# SDHCI register map
File version: 3
SD host controller, SD Host Controller Specification version 3.00 register set
Registers are read-write, no defined reset value unless marked. A register's access mark holds for its fields unless they carry their own. Offsets are from the block's base; lines under a group give offsets from that group; [hi:lo] are bit positions; {n}, {i} and the like mark numbered series; 'fields as' and 'values as' point back to an identical list; <NAME> marks a mode.

## Memory map
0x00000000 SDHCI size 0x100

## SDHCI
Base 0x00000000
0x00 DMA_ADDRESS — SDHCI_DMA_ADDRESS (sdhci.h:102): the SDMA system address, or with host version 4 the 32-bit block count (HC 2.2.1, p.36)
  [31:0] ADDRESS
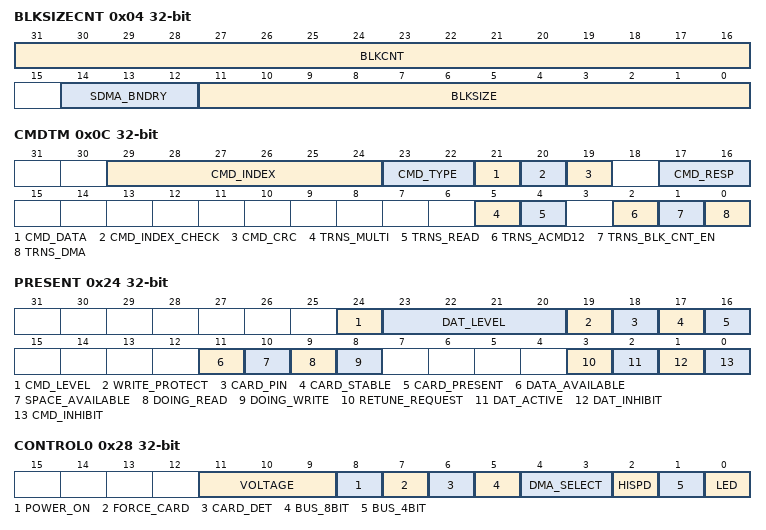
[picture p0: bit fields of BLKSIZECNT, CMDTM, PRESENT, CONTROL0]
0x04 BLKSIZECNT — SDHCI_BLOCK_SIZE and SDHCI_BLOCK_COUNT (sdhci.h:104, 115): block size and 16-bit block count (HC 2.2.2-2.2.3, p.37-39)
  [31:16] BLKCNT — Blocks to transfer (sdhci.h:115)
  [14:12] SDMA_BNDRY — SDMA buffer boundary, 4 KiB shifted left by the value (sdhci.h:105-113)
  [11:0] BLKSIZE — Transfer block size in bytes (sdhci.h:113)
0x08 ARG — SDHCI_ARGUMENT (sdhci.h:117): the command's argument (HC 2.2.4, p.40)
  [31:0] ARGUMENT
0x0C CMDTM — SDHCI_TRANSFER_MODE and SDHCI_COMMAND_FLAGS (sdhci.h:119, 126): transfer mode and command; writing the word issues the command (HC 2.2.5-2.2.6, p.41-47)
  [29:24] CMD_INDEX — Command index, SDHCI_COMMAND (sdhci.h:141); six bits (HC 2.2.6, p.45)
  [23:22] CMD_TYPE — Command type: 0 normal, 1 suspend, 2 resume, 3 abort (sdhci.h:135-139)
    0=NORMAL; 1=SUSPEND; 2=RESUME; 3=ABORT
  [21] CMD_DATA — Data present select (sdhci.h:134)
  [20] CMD_INDEX_CHECK — Command index check enable (sdhci.h:133)
  [19] CMD_CRC — Command CRC check enable (sdhci.h:132)
  [17:16] CMD_RESP — Response type: 0 none, 1 136 bits, 2 48 bits, 3 48 bits with busy (sdhci.h:127-131)
    0=NONE; 1=BITS136; 2=BITS48; 3=BITS48_BUSY
  [5] TRNS_MULTI — Multiple block select (sdhci.h:124)
  [4] TRNS_READ — Data direction: 1 card to host (sdhci.h:123)
  [2] TRNS_ACMD12 — Auto CMD12 enable (sdhci.h:122)
  [1] TRNS_BLK_CNT_EN — Block count enable (sdhci.h:121)
  [0] TRNS_DMA — DMA enable (sdhci.h:120)
{0x10+4i} RESP[{i}] (i=0..3) ro — SDHCI_RESPONSE (sdhci.h:143): response bits 32n to 32n+31 (HC 2.2.7, p.48)
  [31:0] VALUE
0x20 DATA read-modifies — SDHCI_BUFFER (sdhci.h:145): the buffer data port; a read takes the next word from the buffer (HC 2.2.8, p.49)
  [31:0] DATA
0x24 PRESENT ro — SDHCI_PRESENT_STATE (sdhci.h:147) (HC 2.2.9, p.50)
  [24] CMD_LEVEL — CMD line level (sdhci.h:161)
  [23:20] DAT_LEVEL — DAT[3:0] line levels (sdhci.h:160)
  [19] WRITE_PROTECT — Write protect switch level (sdhci.h:159)
  [18] CARD_PIN — Card detect pin level (sdhci.h:158)
  [17] CARD_STABLE — Card state stable (sdhci.h:157)
  [16] CARD_PRESENT — Card inserted (sdhci.h:156)
  [11] DATA_AVAILABLE — Buffer read enable (sdhci.h:155)
  [10] SPACE_AVAILABLE — Buffer write enable (sdhci.h:154)
  [9] DOING_READ — Read transfer active (sdhci.h:153)
  [8] DOING_WRITE — Write transfer active (sdhci.h:152)
  [3] RETUNE_REQUEST — Re-tuning request (sdhci.h:151)
  [2] DAT_ACTIVE — Data line active (sdhci.h:150)
  [1] DAT_INHIBIT — Data lines in use (sdhci.h:149)
  [0] CMD_INHIBIT — Command line in use (sdhci.h:148)
0x28 CONTROL0 — SDHCI_HOST_CONTROL, SDHCI_POWER_CONTROL, SDHCI_BLOCK_GAP_CONTROL and SDHCI_WAKE_UP_CONTROL (sdhci.h:163, 175, 181, 183): host control 1, power, block gap and wakeup (HC 2.2.11-2.2.14, p.60-67); FreeBSD names no bit of the last two
  [11:9] VOLTAGE — SD bus voltage select: 5 1.8 V, 6 3.0 V, 7 3.3 V (sdhci.h:177-179)
    5=V180; 6=V300; 7=V330
  [8] POWER_ON — SD bus power (sdhci.h:176)
  [7] FORCE_CARD — Card detect signal selection: 1 the test level (sdhci.h:173)
  [6] CARD_DET — Card detect test level (sdhci.h:172)
  [5] BUS_8BIT — 8-bit data width (sdhci.h:171)
  [4:3] DMA_SELECT — DMA select: 0 SDMA, 1 reserved, 2 32-bit ADMA2, 3 64-bit ADMA2 (HC 2.2.11, p.60-61; the mask, sdhci.h:170); owned by the NIF
  [2] HISPD — High speed enable (sdhci.h:166)
  [1] BUS_4BIT — 4-bit data width (sdhci.h:165)
  [0] LED — LED control (sdhci.h:164)
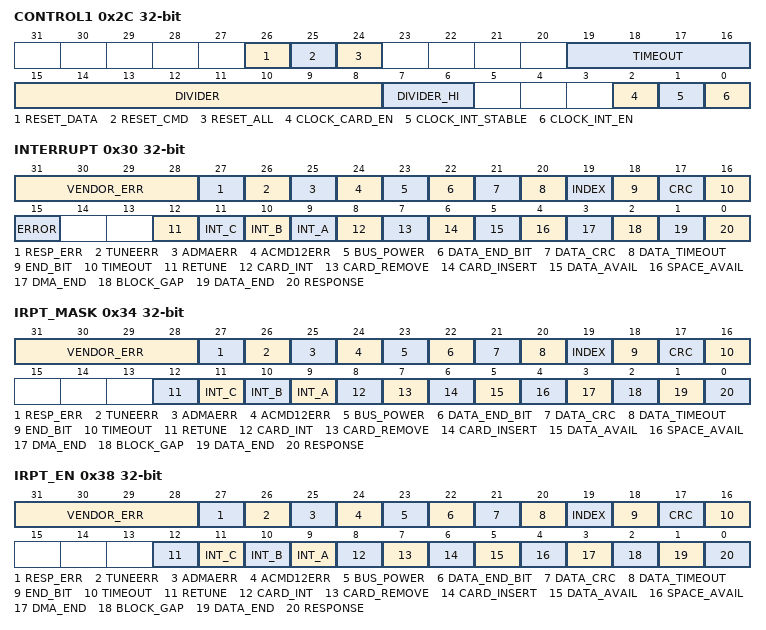
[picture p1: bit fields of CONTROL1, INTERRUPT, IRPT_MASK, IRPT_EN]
0x2C CONTROL1 — SDHCI_CLOCK_CONTROL, SDHCI_TIMEOUT_CONTROL and SDHCI_SOFTWARE_RESET (sdhci.h:185, 198, 200): clock control, data timeout and software reset (HC 2.2.15-2.2.17, p.68-75)
  [26] RESET_DATA — Software reset for the data lines (sdhci.h:203)
  [25] RESET_CMD — Software reset for the command line (sdhci.h:202)
  [24] RESET_ALL — Software reset for all, cleared by the controller when done (sdhci.h:201)
  [19:16] TIMEOUT — Data timeout counter value: the timeout is 2^(13 + value) cycles of the timeout clock (sdhci.h:198; HC 2.2.16, p.73)
    14=MAX
  [15:8] DIVIDER — Bits 7:0 of the 10-bit clock divider (sdhci.h:186-188)
  [7:6] DIVIDER_HI — Bits 9:8 of the 10-bit clock divider (sdhci.h:189-190)
  [2] CLOCK_CARD_EN — SD clock enable (sdhci.h:191)
  [1] CLOCK_INT_STABLE ro — Internal clock stable (sdhci.h:192)
  [0] CLOCK_INT_EN — Internal clock enable (sdhci.h:193)
0x30 INTERRUPT — SDHCI_INT_STATUS (sdhci.h:205): normal and error interrupt status; a status bit is cleared by writing 1, and CARD_INT, INT_A to INT_C, RETUNE and ERROR only follow their sources (HC 2.2.18-2.2.19, p.76-85)
  [31:28] VENDOR_ERR write-1-clears — Vendor-specific error status, four bits (HC 2.2.19, Figure 2-22, p.82)
  [27] RESP_ERR write-1-clears — Response error, which a controller of version 4.00 or later sets when its own check of an R1 or R5 finds an error (HC 2.2.19, Figure 2-22, p.82)
  [26] TUNEERR write-1-clears — Tuning error (sdhci.h:232)
  [25] ADMAERR write-1-clears — ADMA error (sdhci.h:231)
  [24] ACMD12ERR write-1-clears — Auto CMD error (sdhci.h:230)
  [23] BUS_POWER write-1-clears — Current limit error (sdhci.h:229)
  [22] DATA_END_BIT write-1-clears — Data end bit error (sdhci.h:228)
  [21] DATA_CRC write-1-clears — Data CRC error (sdhci.h:227)
  [20] DATA_TIMEOUT write-1-clears — Data timeout error (sdhci.h:226)
  [19] INDEX write-1-clears — Command index error (sdhci.h:225)
  [18] END_BIT write-1-clears — Command end bit error (sdhci.h:224)
  [17] CRC write-1-clears — Command CRC error (sdhci.h:223)
  [16] TIMEOUT write-1-clears — Command timeout error (sdhci.h:222)
  [15] ERROR ro — Some error status bit is set (sdhci.h:221)
  [12] RETUNE ro — Re-tuning event (sdhci.h:220)
  [11] INT_C ro — Embedded INT_C (sdhci.h:219)
  [10] INT_B ro — Embedded INT_B (sdhci.h:218)
  [9] INT_A ro — Embedded INT_A (sdhci.h:217)
  [8] CARD_INT ro — Card interrupt (sdhci.h:216)
  [7] CARD_REMOVE write-1-clears — Card removal (sdhci.h:215)
  [6] CARD_INSERT write-1-clears — Card insertion (sdhci.h:214)
  [5] DATA_AVAIL write-1-clears — Buffer read ready (sdhci.h:213)
  [4] SPACE_AVAIL write-1-clears — Buffer write ready (sdhci.h:212)
  [3] DMA_END write-1-clears — DMA interrupt (sdhci.h:211)
  [2] BLOCK_GAP write-1-clears — Block gap event (sdhci.h:210)
  [1] DATA_END write-1-clears — Transfer complete (sdhci.h:209)
  [0] RESPONSE write-1-clears — Command complete (sdhci.h:208)
0x34 IRPT_MASK — SDHCI_INT_ENABLE (sdhci.h:206): normal and error interrupt status enable, which events set INTERRUPT's bits; bits as INTERRUPT's (HC 2.2.20-2.2.21, p.86-89)
  [31:28] VENDOR_ERR — Vendor-specific error status enable, four bits (HC 2.2.21, Figure 2-24, p.88)
  [27] RESP_ERR — Response error status enable (HC 2.2.21, Figure 2-24, p.88)
  [26] TUNEERR
  [25] ADMAERR
  [24] ACMD12ERR
  [23] BUS_POWER
  [22] DATA_END_BIT
  [21] DATA_CRC
  [20] DATA_TIMEOUT
  [19] INDEX
  [18] END_BIT
  [17] CRC
  [16] TIMEOUT
  [12] RETUNE
  [11] INT_C
  [10] INT_B
  [9] INT_A
  [8] CARD_INT
  [7] CARD_REMOVE
  [6] CARD_INSERT
  [5] DATA_AVAIL
  [4] SPACE_AVAIL
  [3] DMA_END
  [2] BLOCK_GAP
  [1] DATA_END
  [0] RESPONSE
0x38 IRPT_EN — SDHCI_SIGNAL_ENABLE (sdhci.h:207): normal and error interrupt signal enable, which set bits of INTERRUPT raise the line; bits as INTERRUPT's (HC 2.2.22-2.2.23, p.90-93)
  [31:28] VENDOR_ERR — Vendor-specific error signal enable, four bits (HC 2.2.23, Figure 2-26, p.92)
  [27] RESP_ERR — Response error signal enable (HC 2.2.23, Figure 2-26, p.92)
  [26] TUNEERR
  [25] ADMAERR
  [24] ACMD12ERR
  [23] BUS_POWER
  [22] DATA_END_BIT
  [21] DATA_CRC
  [20] DATA_TIMEOUT
  [19] INDEX
  [18] END_BIT
  [17] CRC
  [16] TIMEOUT
  [12] RETUNE
  [11] INT_C
  [10] INT_B
  [9] INT_A
  [8] CARD_INT
  [7] CARD_REMOVE
  [6] CARD_INSERT
  [5] DATA_AVAIL
  [4] SPACE_AVAIL
  [3] DMA_END
  [2] BLOCK_GAP
  [1] DATA_END
  [0] RESPONSE
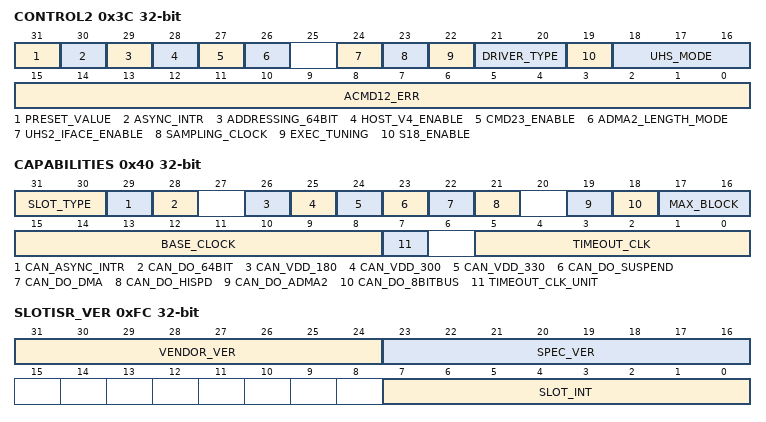
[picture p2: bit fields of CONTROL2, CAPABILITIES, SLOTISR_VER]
0x3C CONTROL2 — SDHCI_ACMD12_ERR and SDHCI_HOST_CONTROL2 (sdhci.h:247, 249): Auto CMD error status and host control 2 (HC 2.2.24-2.2.25, p.94-102)
  [31] PRESET_VALUE — Preset value enable; the driver keeps it clear (sdhci.h:250)
  [30] ASYNC_INTR — Asynchronous interrupt enable (sdhci.h:251)
  [29] ADDRESSING_64BIT — 64-bit addressing; owned by the NIF (sdhci.h:252)
  [28] HOST_V4_ENABLE — Host version 4 enable; owned by the NIF, which keeps it clear (sdhci.h:253)
  [27] CMD23_ENABLE — CMD23 enable (sdhci.h:254)
  [26] ADMA2_LENGTH_MODE — ADMA2 26-bit data length mode; owned by the NIF (sdhci.h:255)
  [24] UHS2_IFACE_ENABLE — UHS-II interface enable (sdhci.h:256)
  [23] SAMPLING_CLOCK — Sampling clock select (sdhci.h:257)
  [22] EXEC_TUNING — Execute tuning (sdhci.h:258)
  [21:20] DRIVER_TYPE — Driver strength select (sdhci.h:259-263)
  [19] S18_ENABLE — 1.8 V signalling enable (sdhci.h:264)
  [18:16] UHS_MODE — UHS mode select (sdhci.h:265-271)
  [15:0] ACMD12_ERR ro — Auto CMD error status, which FreeBSD reads whole (sdhci.h:247)
0x40 CAPABILITIES ro — SDHCI_CAPABILITIES (sdhci.h:273): the low word of the capabilities register (HC 2.2.26, p.103-110)
  [31:30] SLOT_TYPE — Slot type: 0 removable, 1 embedded, 2 shared bus (sdhci.h:292-295)
  [29] CAN_ASYNC_INTR — Asynchronous interrupt support (sdhci.h:291)
  [28] CAN_DO_64BIT — 64-bit system bus support (sdhci.h:290)
  [26] CAN_VDD_180 — 1.8 V support (sdhci.h:289)
  [25] CAN_VDD_300 — 3.0 V support (sdhci.h:288)
  [24] CAN_VDD_330 — 3.3 V support (sdhci.h:287)
  [23] CAN_DO_SUSPEND — Suspend and resume support (sdhci.h:286)
  [22] CAN_DO_DMA — SDMA support (sdhci.h:285)
  [21] CAN_DO_HISPD — High speed support (sdhci.h:284)
  [19] CAN_DO_ADMA2 — ADMA2 support (sdhci.h:283)
  [18] CAN_DO_8BITBUS — 8-bit bus support (sdhci.h:282)
  [17:16] MAX_BLOCK — Maximum block length: 512 bytes shifted left by the value (sdhci.h:280-281)
  [15:8] BASE_CLOCK — Base clock frequency in MHz, version 3.00's eight bits; 0 means another source gives it (sdhci.h:278-279)
  [7] TIMEOUT_CLK_UNIT — Timeout clock unit: 1 MHz, 0 kHz (sdhci.h:276)
  [5:0] TIMEOUT_CLK — Timeout clock frequency (sdhci.h:274-275)
0x58 ADMA_ADDRESS — SDHCI_ADMA_ADDRESS_LO (sdhci.h:324): the ADMA2 descriptor table's address, low word (HC 2.2.31, p.116)
  [31:0] ADDRESS
0xFC SLOTISR_VER ro — SDHCI_SLOT_INT_STATUS and SDHCI_HOST_VERSION (sdhci.h:330, 332): slot interrupt status and host controller version (HC 2.3.15-2.3.16, p.137-138)
  [31:24] VENDOR_VER — Vendor version (sdhci.h:333-334)
  [23:16] SPEC_VER — Specification version: 2 for version 3.00 (sdhci.h:335; HC 2.3.16, p.138)
    2=V300
  [7:0] SLOT_INT — Interrupt signal of each slot, which FreeBSD reads whole (sdhci.h:330; HC 2.3.15, p.137)

## Notices in the file
Copyright (c) 2026, Stanislav Sedov <stas@deglitch.com>
SPDX-License-Identifier: BSD-2-Clause
An SD host controller with the SD Host Controller Specification's version 3.00
register set, the Raspberry Pi 4's EMMC2 (`brcm,bcm2711-emmc2`), written by erXos
from two sources. The SD Association's SD Host Controller Simplified Specification,
version 4.20, gives each register's layout, cited as "HC" with section and printed
page; it is not in the tree, whose redistribution its terms do not grant. FreeBSD's
sys/dev/sdhci/sdhci.h at release/15.1.0
